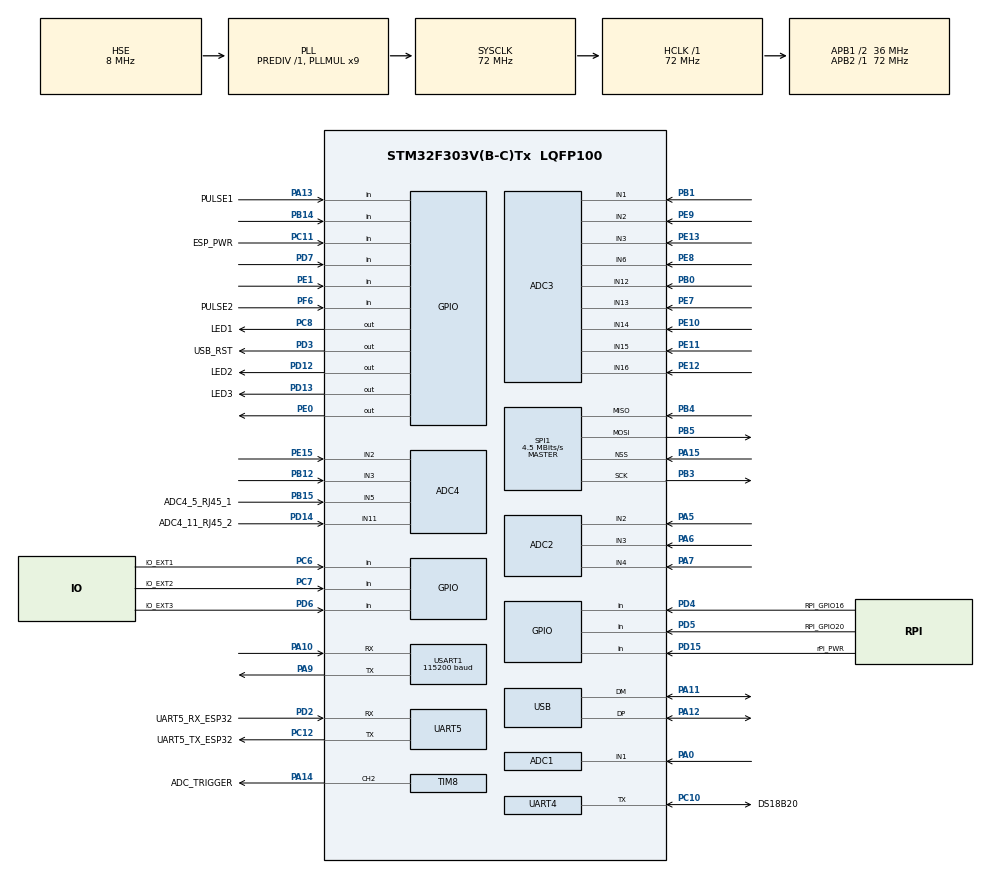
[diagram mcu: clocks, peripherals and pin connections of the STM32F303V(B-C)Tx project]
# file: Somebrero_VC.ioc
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ADC1.Channel-0\#ChannelRegularConversion=ADC_CHANNEL_1
ADC1.ContinuousConvMode=ENABLE
ADC1.DMAContinuousRequests=ENABLE
ADC1.EOCSelection=ADC_EOC_SEQ_CONV
ADC1.ExternalTrigConv=ADC_EXTERNALTRIGCONV_T8_TRGO2
ADC1.NbrOfConversionFlag=1
ADC1.Offset-0\#ChannelRegularConversion=0
ADC1.OffsetNumber-0\#ChannelRegularConversion=ADC_OFFSET_NONE
ADC1.Rank-0\#ChannelRegularConversion=1
ADC1.SamplingTime-0\#ChannelRegularConversion=ADC_SAMPLETIME_181CYCLES_5
ADC1.master=1
ADC2.Channel-0\#ChannelRegularConversion=ADC_CHANNEL_2
ADC2.Channel-1\#ChannelRegularConversion=ADC_CHANNEL_2
ADC2.Channel-2\#ChannelRegularConversion=ADC_CHANNEL_2
ADC2.ContinuousConvMode=ENABLE
ADC2.DMAContinuousRequests=ENABLE
ADC2.DiscontinuousConvMode=DISABLE
ADC2.EOCSelection=ADC_EOC_SEQ_CONV
ADC2.EnableInjectedConversion=DISABLE
ADC2.ExternalTrigConv=ADC_EXTERNALTRIGCONV_T8_TRGO2
ADC2.NbrOfConversion=3
ADC2.NbrOfConversionFlag=1
ADC2.Offset-0\#ChannelRegularConversion=0
ADC2.Offset-1\#ChannelRegularConversion=0
ADC2.Offset-2\#ChannelRegularConversion=0
ADC2.OffsetNumber-0\#ChannelRegularConversion=ADC_OFFSET_NONE
ADC2.OffsetNumber-1\#ChannelRegularConversion=ADC_OFFSET_NONE
ADC2.OffsetNumber-2\#ChannelRegularConversion=ADC_OFFSET_NONE
ADC2.Rank-0\#ChannelRegularConversion=1
ADC2.Rank-1\#ChannelRegularConversion=2
ADC2.Rank-2\#ChannelRegularConversion=3
ADC2.SamplingTime-0\#ChannelRegularConversion=ADC_SAMPLETIME_181CYCLES_5
ADC2.SamplingTime-1\#ChannelRegularConversion=ADC_SAMPLETIME_181CYCLES_5
ADC2.SamplingTime-2\#ChannelRegularConversion=ADC_SAMPLETIME_181CYCLES_5
ADC3.Channel-0\#ChannelRegularConversion=ADC_CHANNEL_12
ADC3.Channel-1\#ChannelRegularConversion=ADC_CHANNEL_1
ADC3.Channel-2\#ChannelRegularConversion=ADC_CHANNEL_13
ADC3.Channel-3\#ChannelRegularConversion=ADC_CHANNEL_6
ADC3.Channel-4\#ChannelRegularConversion=ADC_CHANNEL_2
ADC3.Channel-5\#ChannelRegularConversion=ADC_CHANNEL_14
ADC3.Channel-6\#ChannelRegularConversion=ADC_CHANNEL_15
ADC3.Channel-7\#ChannelRegularConversion=ADC_CHANNEL_16
ADC3.Channel-8\#ChannelRegularConversion=ADC_CHANNEL_3
ADC3.ExternalTrigConv=ADC_EXTERNALTRIGCONV_T8_TRGO2
ADC3.NbrOfConversion=9
ADC3.NbrOfConversionFlag=1
ADC3.Offset-0\#ChannelRegularConversion=0
ADC3.Offset-1\#ChannelRegularConversion=0
ADC3.Offset-2\#ChannelRegularConversion=0
ADC3.Offset-3\#ChannelRegularConversion=0
ADC3.Offset-4\#ChannelRegularConversion=0
ADC3.Offset-5\#ChannelRegularConversion=0
ADC3.Offset-6\#ChannelRegularConversion=0
ADC3.Offset-7\#ChannelRegularConversion=0
ADC3.Offset-8\#ChannelRegularConversion=0
ADC3.OffsetNumber-0\#ChannelRegularConversion=ADC_OFFSET_NONE
ADC3.OffsetNumber-1\#ChannelRegularConversion=ADC_OFFSET_NONE
ADC3.OffsetNumber-2\#ChannelRegularConversion=ADC_OFFSET_NONE
ADC3.OffsetNumber-3\#ChannelRegularConversion=ADC_OFFSET_NONE
ADC3.OffsetNumber-4\#ChannelRegularConversion=ADC_OFFSET_NONE
ADC3.OffsetNumber-5\#ChannelRegularConversion=ADC_OFFSET_NONE
ADC3.OffsetNumber-6\#ChannelRegularConversion=ADC_OFFSET_NONE
ADC3.OffsetNumber-7\#ChannelRegularConversion=ADC_OFFSET_NONE
ADC3.OffsetNumber-8\#ChannelRegularConversion=ADC_OFFSET_NONE
ADC3.Rank-0\#ChannelRegularConversion=1
ADC3.Rank-1\#ChannelRegularConversion=2
ADC3.Rank-2\#ChannelRegularConversion=3
ADC3.Rank-3\#ChannelRegularConversion=4
ADC3.Rank-4\#ChannelRegularConversion=5
ADC3.Rank-5\#ChannelRegularConversion=6
ADC3.Rank-6\#ChannelRegularConversion=7
ADC3.Rank-7\#ChannelRegularConversion=8
ADC3.Rank-8\#ChannelRegularConversion=9
ADC3.SamplingTime-0\#ChannelRegularConversion=ADC_SAMPLETIME_181CYCLES_5
ADC3.SamplingTime-1\#ChannelRegularConversion=ADC_SAMPLETIME_181CYCLES_5
ADC3.SamplingTime-2\#ChannelRegularConversion=ADC_SAMPLETIME_181CYCLES_5
ADC3.SamplingTime-3\#ChannelRegularConversion=ADC_SAMPLETIME_181CYCLES_5
ADC3.SamplingTime-4\#ChannelRegularConversion=ADC_SAMPLETIME_181CYCLES_5
ADC3.SamplingTime-5\#ChannelRegularConversion=ADC_SAMPLETIME_181CYCLES_5
ADC3.SamplingTime-6\#ChannelRegularConversion=ADC_SAMPLETIME_181CYCLES_5
ADC3.SamplingTime-7\#ChannelRegularConversion=ADC_SAMPLETIME_181CYCLES_5
ADC3.SamplingTime-8\#ChannelRegularConversion=ADC_SAMPLETIME_181CYCLES_5
ADC3.master=1
ADC4.Channel-0\#ChannelRegularConversion=ADC_CHANNEL_5
ADC4.NbrOfConversionFlag=1
ADC4.Offset-0\#ChannelRegularConversion=0
ADC4.OffsetNumber-0\#ChannelRegularConversion=ADC_OFFSET_NONE
ADC4.Rank-0\#ChannelRegularConversion=1
ADC4.SamplingTime-0\#ChannelRegularConversion=ADC_SAMPLETIME_1CYCLE_5
Dma.ADC1.1.Direction=DMA_PERIPH_TO_MEMORY
Dma.ADC1.1.Instance=DMA1_Channel1
Dma.ADC1.1.MemDataAlignment=DMA_MDATAALIGN_HALFWORD
Dma.ADC1.1.MemInc=DMA_MINC_ENABLE
Dma.ADC1.1.Mode=DMA_CIRCULAR
Dma.ADC1.1.PeriphDataAlignment=DMA_PDATAALIGN_HALFWORD
Dma.ADC1.1.PeriphInc=DMA_PINC_DISABLE
Dma.ADC1.1.Priority=DMA_PRIORITY_LOW
Dma.ADC2.2.Direction=DMA_PERIPH_TO_MEMORY
Dma.ADC2.2.Instance=DMA2_Channel1
Dma.ADC2.2.MemDataAlignment=DMA_MDATAALIGN_HALFWORD
Dma.ADC2.2.MemInc=DMA_MINC_ENABLE
Dma.ADC2.2.Mode=DMA_CIRCULAR
Dma.ADC2.2.PeriphDataAlignment=DMA_PDATAALIGN_HALFWORD
Dma.ADC2.2.PeriphInc=DMA_PINC_DISABLE
Dma.ADC2.2.Priority=DMA_PRIORITY_LOW
Dma.ADC3.3.Direction=DMA_PERIPH_TO_MEMORY
Dma.ADC3.3.Instance=DMA2_Channel5
Dma.ADC3.3.MemDataAlignment=DMA_MDATAALIGN_HALFWORD
Dma.ADC3.3.MemInc=DMA_MINC_ENABLE
Dma.ADC3.3.Mode=DMA_CIRCULAR
Dma.ADC3.3.PeriphDataAlignment=DMA_PDATAALIGN_HALFWORD
Dma.ADC3.3.PeriphInc=DMA_PINC_DISABLE
Dma.ADC3.3.Priority=DMA_PRIORITY_LOW
Dma.Request0=USART1_RX
Dma.Request1=ADC1
Dma.Request2=ADC2
Dma.Request3=ADC3
Dma.USART1_RX.0.Direction=DMA_PERIPH_TO_MEMORY
Dma.USART1_RX.0.Instance=DMA1_Channel5
Dma.USART1_RX.0.MemDataAlignment=DMA_MDATAALIGN_BYTE
Dma.USART1_RX.0.MemInc=DMA_MINC_ENABLE
Dma.USART1_RX.0.Mode=DMA_NORMAL
Dma.USART1_RX.0.PeriphDataAlignment=DMA_PDATAALIGN_BYTE
Dma.USART1_RX.0.PeriphInc=DMA_PINC_DISABLE
Dma.USART1_RX.0.Priority=DMA_PRIORITY_LOW
Mcu.Family=STM32F3
Mcu.Name=STM32F303V(B-C)Tx
Mcu.Package=LQFP100
NVIC.DMA1_Channel1_IRQn=true\:0\:0\:false\:false\:true\:false
NVIC.DMA1_Channel5_IRQn=true\:0\:0\:false\:false\:true\:false
NVIC.DMA2_Channel1_IRQn=true\:0\:0\:false\:false\:true\:false
NVIC.DMA2_Channel5_IRQn=true\:0\:0\:false\:false\:true\:false
NVIC.PriorityGroup=NVIC_PRIORITYGROUP_4
NVIC.USART1_IRQn=true\:0\:0\:false\:false\:true\:true
PA0.Mode=IN1-Single-Ended
PA0.Signal=ADC1_IN1
PA10.Mode=Asynchronous
PA10.Signal=USART1_RX
PA11.Mode=Device
PA11.Signal=USB_DM
PA12.Mode=Device
PA12.Signal=USB_DP
PA13.GPIO_Label=PULSE1
PA13.Signal=GPIO_Input
PA14.GPIO_Label=ADC_TRIGGER
PA14.Signal=S_TIM8_CH2
PA15.Mode=NSS_Signal_Hard_Input
PA15.Signal=SPI1_NSS
PA5.Mode=IN2-Single-Ended
PA5.Signal=ADC2_IN2
PA6.Mode=IN3-Single-Ended
PA6.Signal=ADC2_IN3
PA7.Mode=IN4-Single-Ended
PA7.Signal=ADC2_IN4
PA9.Mode=Asynchronous
PA9.Signal=USART1_TX
PB0.Mode=IN12-Single-Ended
PB0.Signal=ADC3_IN12
PB1.Mode=IN1-Single-Ended
PB1.Signal=ADC3_IN1
PB12.Mode=IN2-Differential
PB12.Signal=ADC4_IN3
PB14.Signal=GPIO_Input
PB15.GPIO_Label=ADC4_5_RJ45_1
PB15.Mode=IN5-Single-Ended
PB15.Signal=ADC4_IN5
PB3.Mode=Full_Duplex_Master
PB3.Signal=SPI1_SCK
PB4.Mode=Full_Duplex_Master
PB4.Signal=SPI1_MISO
PB5.Mode=Full_Duplex_Master
PB5.Signal=SPI1_MOSI
PC10.GPIO_Label=DS18B20
PC10.Mode=Half_duplex(single_wire_mode)
PC10.Signal=UART4_TX
PC11.GPIO_Label=ESP_PWR
PC11.Signal=GPIO_Input
PC12.GPIO_Label=UART5_TX_ESP32
PC12.Mode=Asynchronous
PC12.Signal=UART5_TX
PC14-OSC32_IN.Mode=LSE-External-Oscillator
PC14-OSC32_IN.Signal=RCC_OSC32_IN
PC15-OSC32_OUT.Mode=LSE-External-Oscillator
PC15-OSC32_OUT.Signal=RCC_OSC32_OUT
PC6.GPIO_Label=IO_EXT1
PC6.Signal=GPIO_Input
PC7.GPIO_Label=IO_EXT2
PC7.Signal=GPIO_Input
PC8.GPIO_Label=LED1
PC8.Signal=GPIO_Output
PD12.GPIO_Label=LED2
PD12.Signal=GPIO_Output
PD13.GPIO_Label=LED3
PD13.Signal=GPIO_Output
PD14.GPIO_Label=ADC4_11_RJ45_2
PD14.Signal=ADCx_IN11
PD15.GPIO_Label=rPi_PWR
PD15.Signal=GPIO_Input
PD2.GPIO_Label=UART5_RX_ESP32
PD2.Mode=Asynchronous
PD2.Signal=UART5_RX
PD3.GPIO_Label=USB_RST
PD3.Signal=GPIO_Output
PD4.GPIO_Label=RPI_GPIO16
PD4.Signal=GPIO_Input
PD5.GPIO_Label=RPI_GPIO20
PD5.Signal=GPIO_Input
PD6.GPIO_Label=IO_EXT3
PD6.Signal=GPIO_Input
PD7.Signal=GPIO_Input
PE0.Signal=GPIO_Output
PE1.Signal=GPIO_Input
PE10.Mode=IN14-Single-Ended
PE10.Signal=ADC3_IN14
PE11.Mode=IN15-Single-Ended
PE11.Signal=ADC3_IN15
PE12.Mode=IN16-Single-Ended
PE12.Signal=ADC3_IN16
PE13.Mode=IN3-Single-Ended
PE13.Signal=ADC3_IN3
PE15.Mode=IN2-Differential
PE15.Signal=ADC4_IN2
PE7.Mode=IN13-Single-Ended
PE7.Signal=ADC3_IN13
PE8.Signal=ADCx_IN6P
PE9.Mode=IN2-Single-Ended
PE9.Signal=ADC3_IN2
PF0-OSC_IN.Mode=HSE-External-Oscillator
PF0-OSC_IN.Signal=RCC_OSC_IN
PF1-OSC_OUT.Mode=HSE-External-Oscillator
PF1-OSC_OUT.Signal=RCC_OSC_OUT
PF6.GPIO_Label=PULSE2
PF6.Signal=GPIO_Input
ProjectManager.HeapSize=0x200
ProjectManager.StackSize=0x400
ProjectManager.TargetToolchain=Makefile
RCC.AHBFreq_Value=72000000
RCC.APB1CLKDivider=RCC_HCLK_DIV2
RCC.APB1Freq_Value=36000000
RCC.APB1TimFreq_Value=72000000
RCC.APB2Freq_Value=72000000
RCC.APB2TimFreq_Value=72000000
RCC.CortexFreq_Value=72000000
RCC.HCLKFreq_Value=72000000
RCC.HSE_VALUE=8000000
RCC.HSI_VALUE=8000000
RCC.PLLMUL=RCC_PLL_MUL9
RCC.PRESCALERUSB=RCC_USBCLKSOURCE_PLL_DIV1_5
RCC.SYSCLKFreq_VALUE=72000000
RCC.SYSCLKSourceVirtual=RCC_SYSCLKSOURCE_PLLCLK
RCC.USBFreq_Value=48000000
RCC.Uart4ClockSelection=RCC_UART4CLKSOURCE_SYSCLK
RCC.Uart5ClockSelection=RCC_UART5CLKSOURCE_SYSCLK
SH.ADCx_IN11.0=ADC4_IN11,IN11-Single-Ended
SH.ADCx_IN6P.0=ADC3_IN6,IN6-Single-Ended
SH.S_TIM8_CH2.0=TIM8_CH2,Output Compare2 CH2
SPI1.BaudRatePrescaler=SPI_BAUDRATEPRESCALER_16
SPI1.CalculateBaudRate=4.5 MBits/s
SPI1.DataSize=SPI_DATASIZE_8BIT
SPI1.Direction=SPI_DIRECTION_2LINES
SPI1.Mode=SPI_MODE_MASTER
SPI1.VirtualNSS=VM_NSSHARD
SPI1.VirtualType=VM_MASTER
TIM8.Channel-Output\ Compare2\ CH2=TIM_CHANNEL_2
USART1.BaudRate=115200
USART1.VirtualMode-Asynchronous=VM_ASYNC
board=custom

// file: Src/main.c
/**
  ******************************************************************************
  * @file           : main.c
  * @brief          : Main program body
  ******************************************************************************
  ** This notice applies to any and all portions of this file
  * that are not between comment pairs USER CODE BEGIN and
  * USER CODE END. Other portions of this file, whether
  * inserted by the user or by software development tools
  * are owned by their respective copyright owners.
  *
  * COPYRIGHT(c) 2021 STMicroelectronics
  *
  * Redistribution and use in source and binary forms, with or without modification,
  * are permitted provided that the following conditions are met:
  *   1. Redistributions of source code must retain the above copyright notice,
  *      this list of conditions and the following disclaimer.
  *   2. Redistributions in binary form must reproduce the above copyright notice,
  *      this list of conditions and the following disclaimer in the documentation
  *      and/or other materials provided with the distribution.
  *   3. Neither the name of STMicroelectronics nor the names of its contributors
  *      may be used to endorse or promote products derived from this software
  *      without specific prior written permission.
  *
  * THIS SOFTWARE IS PROVIDED BY THE COPYRIGHT HOLDERS AND CONTRIBUTORS "AS IS"
  * AND ANY EXPRESS OR IMPLIED WARRANTIES, INCLUDING, BUT NOT LIMITED TO, THE
  * IMPLIED WARRANTIES OF MERCHANTABILITY AND FITNESS FOR A PARTICULAR PURPOSE ARE
  * DISCLAIMED. IN NO EVENT SHALL THE COPYRIGHT HOLDER OR CONTRIBUTORS BE LIABLE
  * FOR ANY DIRECT, INDIRECT, INCIDENTAL, SPECIAL, EXEMPLARY, OR CONSEQUENTIAL
  * DAMAGES (INCLUDING, BUT NOT LIMITED TO, PROCUREMENT OF SUBSTITUTE GOODS OR
  * SERVICES; LOSS OF USE, DATA, OR PROFITS; OR BUSINESS INTERRUPTION) HOWEVER
  * CAUSED AND ON ANY THEORY OF LIABILITY, WHETHER IN CONTRACT, STRICT LIABILITY,
  * OR TORT (INCLUDING NEGLIGENCE OR OTHERWISE) ARISING IN ANY WAY OUT OF THE USE
  * OF THIS SOFTWARE, EVEN IF ADVISED OF THE POSSIBILITY OF SUCH DAMAGE.
  *
  ******************************************************************************
  */
#include "main.h"
#include "stm32f3xx_hal.h"
#include "adc.h"
#include "dma.h"
#include "spi.h"
#include "tim.h"
#include "usart.h"
#include "usb.h"
#include "gpio.h"

/* USER CODE BEGIN PV */
/* Private variables ---------------------------------------------------------*/

/* USER CODE END PV */

void SystemClock_Config(void);

/* USER CODE BEGIN PFP */
/* Private function prototypes -----------------------------------------------*/

/* USER CODE END PFP */

int main(void)
{

  /* MCU Configuration----------------------------------------------------------*/

  /* Reset of all peripherals, Initializes the Flash interface and the Systick. */
  HAL_Init();

  /* Configure the system clock */
  SystemClock_Config();

  /* Initialize all configured peripherals */
  MX_GPIO_Init();
  MX_DMA_Init();
  MX_USB_PCD_Init();
  MX_ADC4_Init();
  MX_USART1_UART_Init();
  MX_UART4_Init();
  MX_TIM8_Init();
  MX_SPI1_Init();
  MX_ADC3_Init();
  MX_ADC2_Init();
  MX_ADC1_Init();
  MX_UART5_Init();

  /* Infinite loop */
  /* USER CODE BEGIN WHILE */
  while (1)
  {
    HAL_GPIO_TogglePin(LED1_GPIO_Port, LED1_Pin);
    HAL_GPIO_TogglePin(LED2_GPIO_Port, LED2_Pin);
    HAL_GPIO_TogglePin(LED3_GPIO_Port, LED3_Pin);
    HAL_Delay(500);

  /* USER CODE END WHILE */

  }

}

void SystemClock_Config(void)
{

  RCC_OscInitTypeDef RCC_OscInitStruct;
  RCC_ClkInitTypeDef RCC_ClkInitStruct;
  RCC_PeriphCLKInitTypeDef PeriphClkInit;

    /**Initializes the CPU, AHB and APB busses clocks
    */
  RCC_OscInitStruct.OscillatorType = RCC_OSCILLATORTYPE_HSE;
  RCC_OscInitStruct.HSEState = RCC_HSE_ON;
  RCC_OscInitStruct.HSEPredivValue = RCC_HSE_PREDIV_DIV1;
  RCC_OscInitStruct.HSIState = RCC_HSI_ON;
  RCC_OscInitStruct.PLL.PLLState = RCC_PLL_ON;
  RCC_OscInitStruct.PLL.PLLSource = RCC_PLLSOURCE_HSE;
  RCC_OscInitStruct.PLL.PLLMUL = RCC_PLL_MUL9;
  if (HAL_RCC_OscConfig(&RCC_OscInitStruct) != HAL_OK)
  {
    _Error_Handler(__FILE__, __LINE__);
  }

    /**Initializes the CPU, AHB and APB busses clocks
    */
  RCC_ClkInitStruct.ClockType = RCC_CLOCKTYPE_HCLK|RCC_CLOCKTYPE_SYSCLK
                              |RCC_CLOCKTYPE_PCLK1|RCC_CLOCKTYPE_PCLK2;
  RCC_ClkInitStruct.SYSCLKSource = RCC_SYSCLKSOURCE_PLLCLK;
  RCC_ClkInitStruct.AHBCLKDivider = RCC_SYSCLK_DIV1;
  RCC_ClkInitStruct.APB1CLKDivider = RCC_HCLK_DIV2;
  RCC_ClkInitStruct.APB2CLKDivider = RCC_HCLK_DIV1;

  if (HAL_RCC_ClockConfig(&RCC_ClkInitStruct, FLASH_LATENCY_2) != HAL_OK)
  {
    _Error_Handler(__FILE__, __LINE__);
  }

  PeriphClkInit.PeriphClockSelection = RCC_PERIPHCLK_USB|RCC_PERIPHCLK_USART1
                              |RCC_PERIPHCLK_UART4|RCC_PERIPHCLK_UART5
                              |RCC_PERIPHCLK_TIM8|RCC_PERIPHCLK_ADC12
                              |RCC_PERIPHCLK_ADC34;
  PeriphClkInit.Usart1ClockSelection = RCC_USART1CLKSOURCE_PCLK2;
  PeriphClkInit.Uart4ClockSelection = RCC_UART4CLKSOURCE_SYSCLK;
  PeriphClkInit.Uart5ClockSelection = RCC_UART5CLKSOURCE_SYSCLK;
  PeriphClkInit.Adc12ClockSelection = RCC_ADC12PLLCLK_DIV1;
  PeriphClkInit.Adc34ClockSelection = RCC_ADC34PLLCLK_DIV1;
  PeriphClkInit.USBClockSelection = RCC_USBCLKSOURCE_PLL_DIV1_5;
  PeriphClkInit.Tim8ClockSelection = RCC_TIM8CLK_HCLK;
  if (HAL_RCCEx_PeriphCLKConfig(&PeriphClkInit) != HAL_OK)
  {
    _Error_Handler(__FILE__, __LINE__);
  }

    /**Configure the Systick interrupt time
    */
  HAL_SYSTICK_Config(HAL_RCC_GetHCLKFreq()/1000);

    /**Configure the Systick
    */
  HAL_SYSTICK_CLKSourceConfig(SYSTICK_CLKSOURCE_HCLK);

  /* SysTick_IRQn interrupt configuration */
  HAL_NVIC_SetPriority(SysTick_IRQn, 0, 0);
}

void _Error_Handler(char *file, int line)
{
  while(1)
  {
  }
}

/************************ (C) COPYRIGHT STMicroelectronics *****END OF FILE****/
